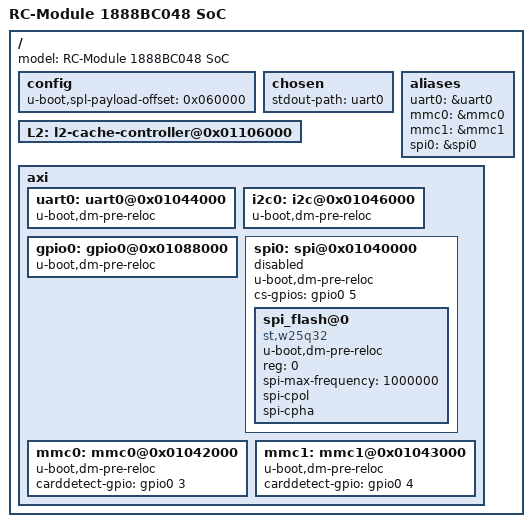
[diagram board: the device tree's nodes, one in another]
/*
 * Device Tree Source for RCM MT143-05 mainboard
 *
 * This file is licensed under the terms of the GNU General Public
 * License version 2.  This program is licensed "as is" without
 * any warranty of any kind, whether express or implied.
 */

#include "1888bc048.dtsi"

/ {
	model = "RC-Module 1888BC048 SoC";

	config {
		u-boot,spl-payload-offset = <0x060000>; 
	};

	chosen {
		stdout-path = "uart0";
	};

	aliases {
		uart0 = &uart0;
		mmc0 = &mmc0;
		mmc1 = &mmc1;
		spi0 = &spi0;
	};

	L2: l2-cache-controller@0x01106000 {
		status = "okay";
	};

	axi {
		uart0: uart0@0x01044000 {
			status = "okay";
			u-boot,dm-pre-reloc;
		};

		i2c0: i2c@0x01046000 {
			status = "okay";
			u-boot,dm-pre-reloc;
		};

		gpio0: gpio0@0x01088000 {
			status = "okay";
			u-boot,dm-pre-reloc;
		};

		spi0: spi@0x01040000 {
			status = "disable";
			u-boot,dm-pre-reloc;
			cs-gpios = <&gpio0 5 0>;
			
			spi_flash@0 {
				u-boot,dm-pre-reloc;
				compatible = "st,w25q32", "spi-flash";
				reg = <0>;
				spi-max-frequency = <1000000>;
				spi-cpol;
				spi-cpha;
			};
		};

		mmc0: mmc0@0x01042000 {
			status = "okay";
			u-boot,dm-pre-reloc;
			carddetect-gpio = <&gpio0 3 0>;
		};

		mmc1: mmc1@0x01043000 {
			status = "okay";
			u-boot,dm-pre-reloc;
			carddetect-gpio = <&gpio0 4 0>;
		};
	};
};

// Ethernet
#include "mt143-02.dtsi"
